# NUC100CN_v1 register map
File version: 1.0
Registers are 32-bit, read-write, reset 0x0 unless marked. A register's access mark holds for its fields unless they carry their own. Offsets are from the block's base; [hi:lo] are bit positions; {n}, {i} and the like mark numbered series; 'fields as' and 'values as' point back to an identical list.

## GP — GP Register Map
Base 0x50004000
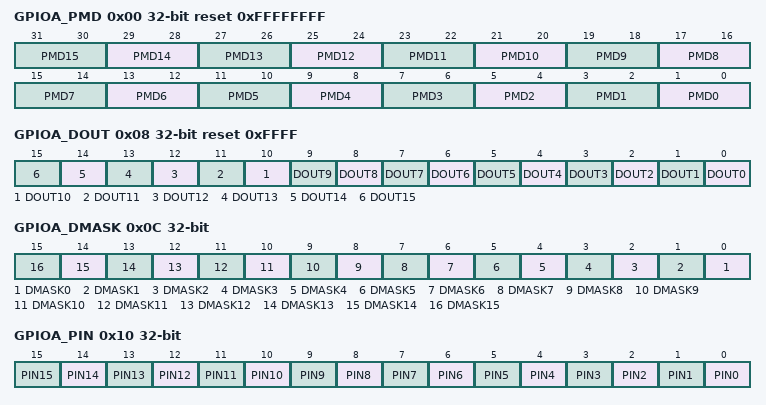
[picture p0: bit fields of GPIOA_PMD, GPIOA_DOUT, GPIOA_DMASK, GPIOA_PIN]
0x00 GPIOA_PMD reset 0xFFFFFFFF — GPIO Port A Pin I/O Mode Control
  [all] fields
    0=GPIO port [n] pin is in INPUT mode; 1=GPIO port [n] pin is in OUTPUT mode; 2=GPIO port [n] pin is in Open-Drain mode; 3=GPIO port [n] pin is in Quasi-bidirectional mode
  [2n+1:2n] PMD{n} (n=0..15) — GPIOx I/O Pin[n] Mode Control. Determine each I/O type of GPIOx pins.
0x04 GPIOA_OFFD — GPIO Port A Pin Digital Input Path Disable Control
  [31:16] OFFD — GPIOx Pin[n] Digital Input Path Disable Control. Each of these bits is used to control if the digital input path of corresponding GPIO pin is disabled. If input is analog signal, users can disable GPIO digital input path to avoid creepage
    0=I/O digital input path Enabled; 1=I/O digital input path Disabled (digital input tied to low)
0x08 GPIOA_DOUT reset 0xFFFF — GPIO Port A Data Output Value
  [all] fields
    0=GPIO port [A/B/C/D/E] Pin[n] will drive Low if the GPIO pin is configures as output, open-drain and quasi-mode; 1=GPIO port [A/B/C/D/E] Pin[n] will drive High if the GPIO pin is configures as output, open-drain and quasi-mode
  [n] DOUT{n} (n=0..15) — GPIOx Pin[n] Output Value. Each of these bits control the status of a GPIO pin when the GPIO pin is configures as output, open-drain and quasi-mode.
0x0C GPIOA_DMASK — GPIO Port A Data Output Write Mask
  [all] fields
    0=The corresponding GPIOx_DOUT[n] bit can be updated; 1=The corresponding GPIOx_DOUT[n] bit is protected
  [n] DMASK{n} (n=0..15) — Port [A/B/C/D/E] Data Output Write Mask. These bits are used to protect the corresponding register of GPIOx_DOUT bit[n]. When set the DMASK bit[n] to 1, the corresponding GPIOx_DOUT[n] bit is protected. The write signal is masked, write data to the protect bit is ignored. Note: This function only protect corresponding GPIOx_DOUT[n] bit, and will not protect corresponding bit control register (GPIOAx_DOUT, GPIOBx_DOUT, GPIOCx_DOUT, GPIODx_DOUT, GPIOEx_DOUT).
0x10 GPIOA_PIN ro (reset mask 0xFFFF0000) — GPIO Port A Pin Value
  [n] PIN{n} (n=0..15) — Port [A/B/C/D/E] Pin Values. Each bit of the register reflects the actual status of the respective GPIO pin If bit is 1, it indicates the corresponding pin status is high, else the pin status is low
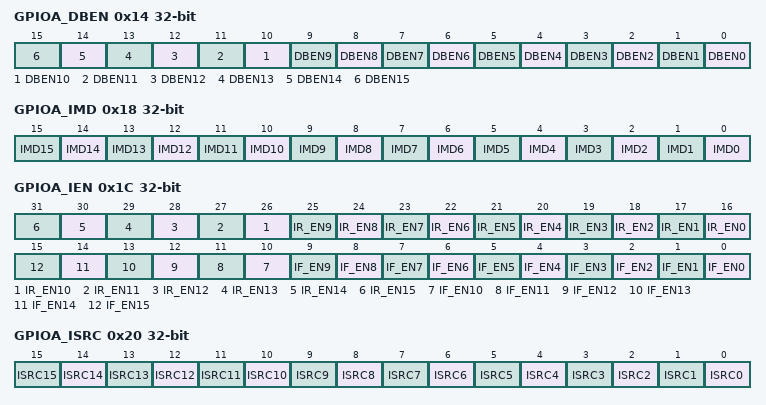
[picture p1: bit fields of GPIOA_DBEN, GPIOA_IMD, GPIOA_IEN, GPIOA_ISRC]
0x14 GPIOA_DBEN — GPIO Port A De-bounce Enable
  [all] fields
    0=The bit[n] de-bounce function Disabled; 1=The bit[n] de-bounce function Enabled
  [n] DBEN{n} (n=0..15) — Port [A/B/C/D/E] Input Signal De-bounce Enable. DBEN[n]used to enable the de-bounce function for each corresponding bit. If the input signal pulse width cannot be sampled by continuous two de-bounce sample cycle The input signal transition is seen as the signal bounce and will not trigger the interrupt. The de-bounce clock source is controlled by DBNCECON[4], one de-bounce sample cycle is controlled by DBNCECON[3:0]. The de-bounce function is valid for edge triggered interrupt. If the interrupt mode is level triggered, the de-bounce enable bit is ignored. Note: It is recommended setting this bit to '0' if GPIO is chosen as power down wakeup source. If set this bit to '1', will cause GPIO to produce interrupt twice. One is caused by wake up event, the other one is caused by delayed de-bounce result.
0x18 GPIOA_IMD — GPIO Port A Interrupt Mode Control
  [all] fields
    0=Edge trigger interrupt; 1=Level trigger interrupt
  [n] IMD{n} (n=0..15) — Port [A/B/C/D/E] Edge or Level Detection Interrupt Control. IMD[n] is used to control the interrupt is by level trigger or by edge trigger. If the interrupt is by edge trigger, the trigger source can be controlled by de-bounce. If the interrupt is by level trigger, the input source is sampled by one HCLK clock and generates the interrupt. If set pin as the level trigger interrupt, then only one level can be set on the registers GPIOx_IEN. If set both the level to trigger interrupt, the setting is ignored and no interrupt will occur. The de-bounce function is valid for edge triggered interrupt. If the interrupt mode is level triggered, the de-bounce enable bit is ignored.
0x1C GPIOA_IEN — GPIO Port A Interrupt Enable
  [n+16] IR_EN{n} (n=0..15) — Port [A/B/C/D/E] Interrupt Enable by Input Rising Edge or Input Level High. IR_EN[n] used to enable the interrupt for each of the corresponding input GPIO_PIN[n]. Set bit to 1 also enable the pin wake-up function. When set the IR_EN[n] bit to 1: If the interrupt is level trigger, the input PIN[n] state at level "high" will generate the interrupt. If the interrupt is edge trigger, the input PIN[n] state change from "low-to-high" will generate the interrupt.
    0=PIN[n] level-high or low-to-high interrupt Disabled; 1=PIN[n] level-high or low-to-high interrupt Enabled
  [n] IF_EN{n} (n=0..15) — Port [A/B/C/D/E] Interrupt Enable by Input Falling Edge or Input Level Low. IF_EN[n] used to enable the interrupt for each of the corresponding input GPIO_PIN[n]. Set bit to 1 also enable the pin wake-up function. When set the IF_EN[n] bit to 1: If the interrupt is level trigger, the input PIN[n] state at level "low" will generate the interrupt. If the interrupt is edge trigger, the input PIN[n] state change from "high-to-low" will generate the interrupt.
    0=PIN[n] state low-level or high-to-low change interrupt Disabled; 1=PIN[n] state low-level or high-to-low change interrupt Enabled
0x20 GPIOA_ISRC reset not defined — GPIO Port A Interrupt Source Flag
  [all] fields
    0=No interrupt at GPIOx[n]. No action; 1=Indicates GPIOx[n] generate an interrupt. Clear the correspond pending interrupt
  [n] ISRC{n} (n=0..15) — Port [A/B/C/D/E] Interrupt Source Flag. Read :
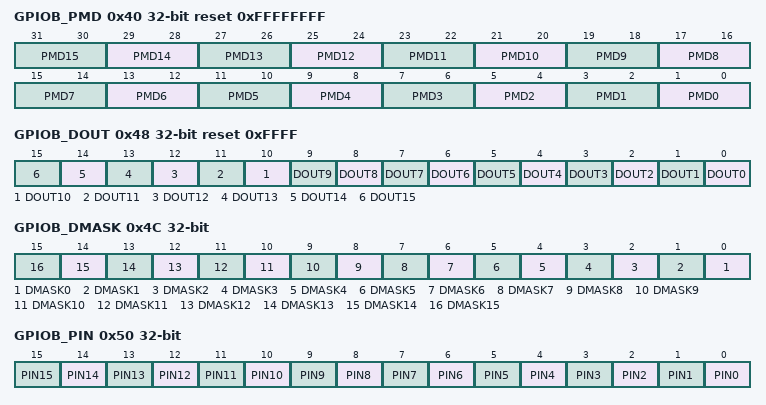
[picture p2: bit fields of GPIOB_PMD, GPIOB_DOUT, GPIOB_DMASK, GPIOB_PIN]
0x40 GPIOB_PMD reset 0xFFFFFFFF — GPIO Port B Pin I/O Mode Control
  fields as GPIOA_PMD
0x44 GPIOB_OFFD — GPIO Port B Pin Digital Input Path Disable Control
  fields as GPIOA_OFFD
0x48 GPIOB_DOUT reset 0xFFFF — GPIO Port B Data Output Value
  fields as GPIOA_DOUT
0x4C GPIOB_DMASK — GPIO Port B Data Output Write Mask
  fields as GPIOA_DMASK
0x50 GPIOB_PIN ro (reset mask 0xFFFF0000) — GPIO Port B Pin Value
  fields as GPIOA_PIN
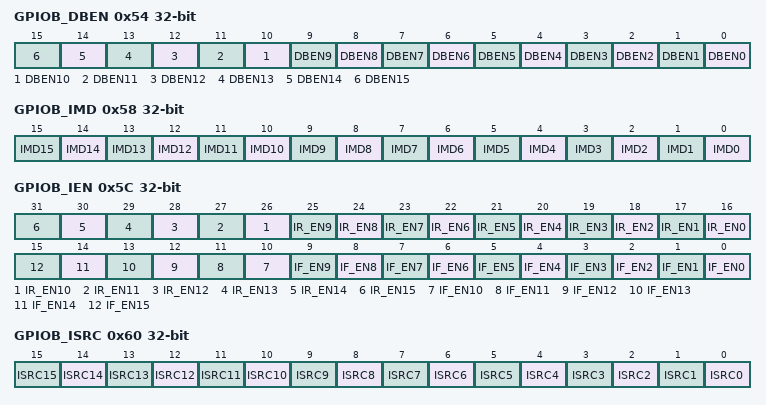
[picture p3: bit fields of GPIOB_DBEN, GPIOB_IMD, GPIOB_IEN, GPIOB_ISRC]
0x54 GPIOB_DBEN — GPIO Port B De-bounce Enable
  fields as GPIOA_DBEN
0x58 GPIOB_IMD — GPIO Port B Interrupt Mode Control
  fields as GPIOA_IMD
0x5C GPIOB_IEN — GPIO Port B Interrupt Enable
  fields as GPIOA_IEN
0x60 GPIOB_ISRC reset not defined — GPIO Port B Interrupt Source Flag
  fields as GPIOA_ISRC
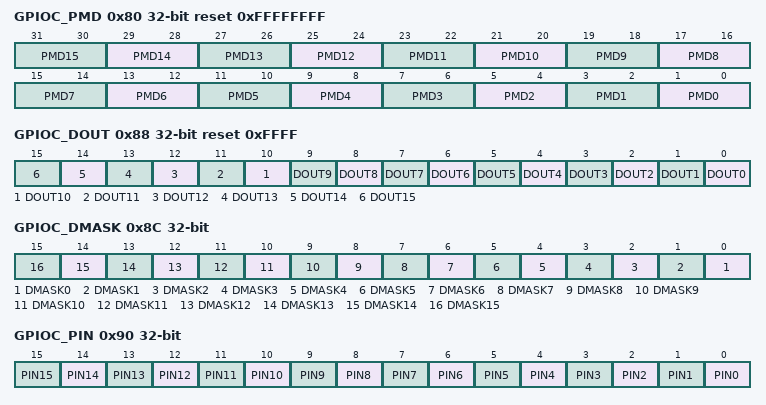
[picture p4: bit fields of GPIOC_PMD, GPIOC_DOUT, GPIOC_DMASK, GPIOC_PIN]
0x80 GPIOC_PMD reset 0xFFFFFFFF — GPIO Port C Pin I/O Mode Control
  fields as GPIOA_PMD
0x84 GPIOC_OFFD — GPIO Port C Pin Digital Input Path Disable Control
  fields as GPIOA_OFFD
0x88 GPIOC_DOUT reset 0xFFFF — GPIO Port C Data Output Value
  fields as GPIOA_DOUT
0x8C GPIOC_DMASK — GPIO Port C Data Output Write Mask
  fields as GPIOA_DMASK
0x90 GPIOC_PIN ro (reset mask 0xFFFF0000) — GPIO Port C Pin Value
  fields as GPIOA_PIN
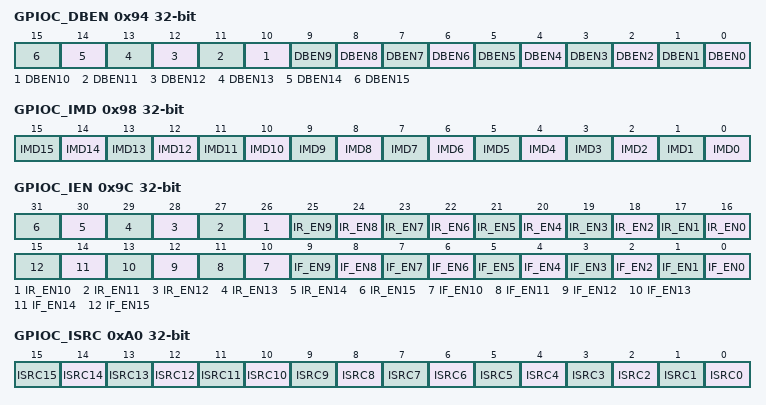
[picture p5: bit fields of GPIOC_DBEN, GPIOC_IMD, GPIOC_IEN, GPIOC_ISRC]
0x94 GPIOC_DBEN — GPIO Port C De-bounce Enable
  fields as GPIOA_DBEN
0x98 GPIOC_IMD — GPIO Port C Interrupt Mode Control
  fields as GPIOA_IMD
0x9C GPIOC_IEN — GPIO Port C Interrupt Enable
  fields as GPIOA_IEN
0xA0 GPIOC_ISRC reset not defined — GPIO Port C Interrupt Source Flag
  fields as GPIOA_ISRC
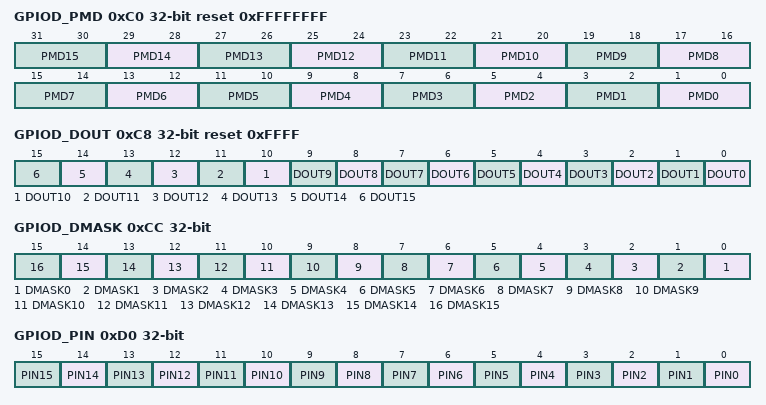
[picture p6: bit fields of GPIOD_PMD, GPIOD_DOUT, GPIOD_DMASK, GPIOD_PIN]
0xC0 GPIOD_PMD reset 0xFFFFFFFF — GPIO Port D Pin I/O Mode Control
  fields as GPIOA_PMD
0xC4 GPIOD_OFFD — GPIO Port D Pin Digital Input Path Disable Control
  fields as GPIOA_OFFD
0xC8 GPIOD_DOUT reset 0xFFFF — GPIO Port D Data Output Value
  fields as GPIOA_DOUT
0xCC GPIOD_DMASK — GPIO Port D Data Output Write Mask
  fields as GPIOA_DMASK
0xD0 GPIOD_PIN ro (reset mask 0xFFFF0000) — GPIO Port D Pin Value
  fields as GPIOA_PIN
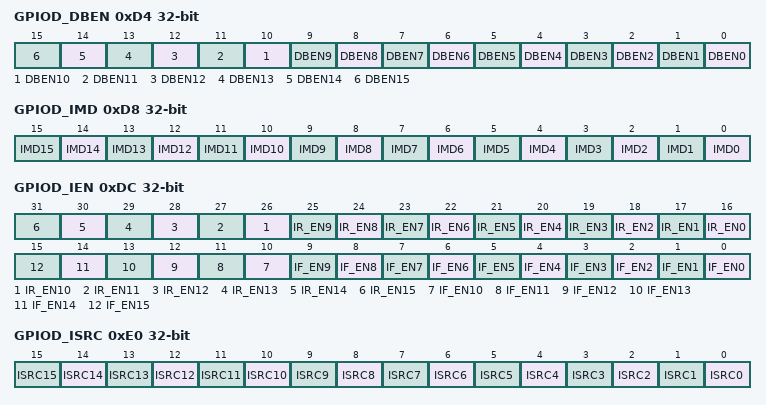
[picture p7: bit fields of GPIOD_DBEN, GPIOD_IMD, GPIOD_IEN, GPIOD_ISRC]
0xD4 GPIOD_DBEN — GPIO Port D De-bounce Enable
  fields as GPIOA_DBEN
0xD8 GPIOD_IMD — GPIO Port D Interrupt Mode Control
  fields as GPIOA_IMD
0xDC GPIOD_IEN — GPIO Port D Interrupt Enable
  fields as GPIOA_IEN
0xE0 GPIOD_ISRC reset not defined — GPIO Port D Interrupt Source Flag
  fields as GPIOA_ISRC
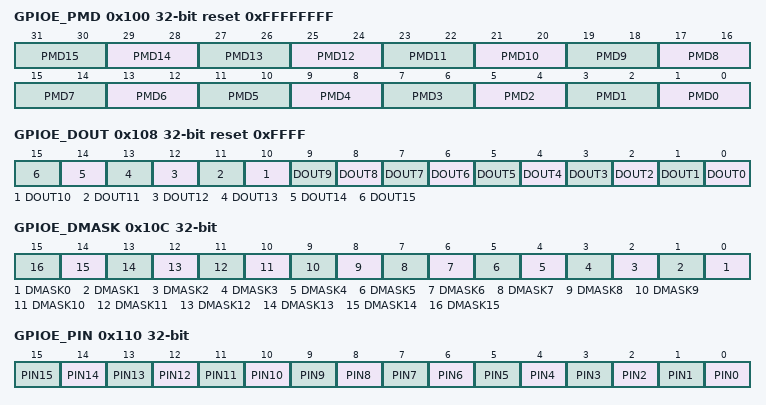
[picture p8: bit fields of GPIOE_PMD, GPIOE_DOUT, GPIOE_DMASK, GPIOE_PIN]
0x100 GPIOE_PMD reset 0xFFFFFFFF — GPIO Port E Pin I/O Mode Control
  fields as GPIOA_PMD
0x104 GPIOE_OFFD — GPIO Port E Pin Digital Input Path Disable Control
  fields as GPIOA_OFFD
0x108 GPIOE_DOUT reset 0xFFFF — GPIO Port E Data Output Value
  fields as GPIOA_DOUT
0x10C GPIOE_DMASK — GPIO Port E Data Output Write Mask
  fields as GPIOA_DMASK
0x110 GPIOE_PIN ro (reset mask 0xFFFF0000) — GPIO Port E Pin Value
  fields as GPIOA_PIN
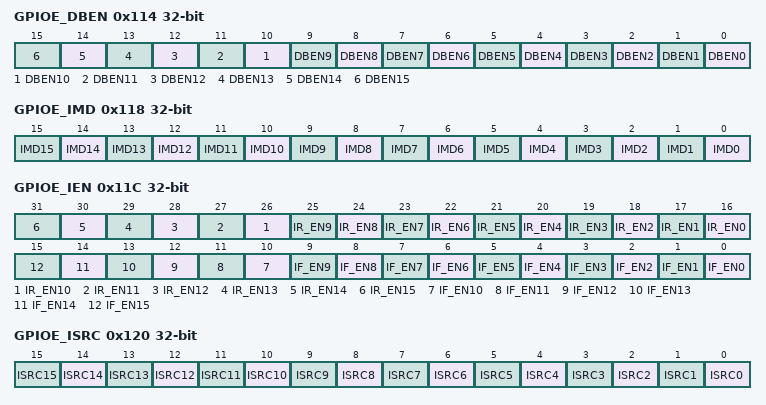
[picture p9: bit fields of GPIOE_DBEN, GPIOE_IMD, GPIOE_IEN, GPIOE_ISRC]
0x114 GPIOE_DBEN — GPIO Port E De-bounce Enable
  fields as GPIOA_DBEN
0x118 GPIOE_IMD — GPIO Port E Interrupt Mode Control
  fields as GPIOA_IMD
0x11C GPIOE_IEN — GPIO Port E Interrupt Enable
  fields as GPIOA_IEN
0x120 GPIOE_ISRC reset not defined — GPIO Port E Interrupt Source Flag
  fields as GPIOA_ISRC
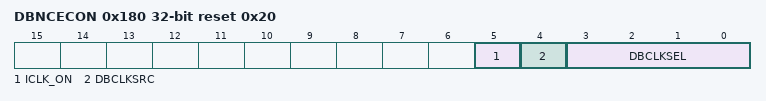
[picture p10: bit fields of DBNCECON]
0x180 DBNCECON reset 0x20 — De-bounce Cycle Control
  [5] ICLK_ON — Interrupt clock On mode. It is recommended to turn off this bit to save system power, if on special application concern.
    0=Edge detection circuit is active only if the I/O pin corresponding to GPIOx_IEN bit is set to 1; 1=All I/O pins edge detection circuit is always active after reset
  [4] DBCLKSRC — De-bounce counter clock source select
    0=De-bounce counter clock source is the HCLK; 1=De-bounce counter clock source is the internal 10 kHz low speed oscillator
  [3:0] DBCLKSEL — De-bounce sampling cycle selection
0x200 PA0_PDIO reset 0x1 — GPIO PA.0 Pin Data I/O
  [0] Pxn_PDIO — GPIO Px.n Pin Data I/O. Write this bit can control one GPIO pin output value. Read this register to get GPIO pin status. For example: write PA0_PDIO will reflect the written value to bit GPIOA_DOUT[0], read PA0_PDIO will return the value of GPIOA_PIN[0]. Note: The write operation will not be affected by register GPIOx_DMASK
    0=Set corresponding GPIO pin to low; 1=Set corresponding GPIO pin to high
0x204 PA1_PDIO reset 0x1 — GPIO PA.1 Pin Data I/O
  fields as PA0_PDIO
0x208 PA2_PDIO reset 0x1 — GPIO PA.2 Pin Data I/O
  fields as PA0_PDIO
0x20C PA3_PDIO reset 0x1 — GPIO PA.3 Pin Data I/O
  fields as PA0_PDIO
0x210 PA4_PDIO reset 0x1 — GPIO PA.4 Pin Data I/O
  fields as PA0_PDIO
0x214 PA5_PDIO reset 0x1 — GPIO PA.5 Pin Data I/O
  fields as PA0_PDIO
0x218 PA6_PDIO reset 0x1 — GPIO PA.6 Pin Data I/O
  fields as PA0_PDIO
0x21C PA7_PDIO reset 0x1 — GPIO PA.7 Pin Data I/O
  fields as PA0_PDIO
0x220 PA8_PDIO reset 0x1 — GPIO PA.8 Pin Data I/O
  fields as PA0_PDIO
0x224 PA9_PDIO reset 0x1 — GPIO PA.9 Pin Data I/O
  fields as PA0_PDIO
0x228 PA10_PDIO reset 0x1 — GPIO PA.10 Pin Data I/O
  fields as PA0_PDIO
0x22C PA11_PDIO reset 0x1 — GPIO PA.11 Pin Data I/O
  fields as PA0_PDIO
0x230 PA12_PDIO reset 0x1 — GPIO PA.12 Pin Data I/O
  fields as PA0_PDIO
0x234 PA13_PDIO reset 0x1 — GPIO PA.13 Pin Data I/O
  fields as PA0_PDIO
0x238 PA14_PDIO reset 0x1 — GPIO PA.14 Pin Data I/O
  fields as PA0_PDIO
0x23C PA15_PDIO reset 0x1 — GPIO PA.15 Pin Data I/O
  fields as PA0_PDIO
0x240 PB0_PDIO reset 0x1 — GPIO PB.0 Pin Data I/O
  fields as PA0_PDIO
0x244 PB1_PDIO reset 0x1 — GPIO PB.1 Pin Data I/O
  fields as PA0_PDIO
0x248 PB2_PDIO reset 0x1 — GPIO PB.2 Pin Data I/O
  fields as PA0_PDIO
0x24C PB3_PDIO reset 0x1 — GPIO PB.3 Pin Data I/O
  fields as PA0_PDIO
0x250 PB4_PDIO reset 0x1 — GPIO PB.4 Pin Data I/O
  fields as PA0_PDIO
0x254 PB5_PDIO reset 0x1 — GPIO PB.5 Pin Data I/O
  fields as PA0_PDIO
0x258 PB6_PDIO reset 0x1 — GPIO PB.6 Pin Data I/O
  fields as PA0_PDIO
0x25C PB7_PDIO reset 0x1 — GPIO PB.7 Pin Data I/O
  fields as PA0_PDIO
0x260 PB8_PDIO reset 0x1 — GPIO PB.8 Pin Data I/O
  fields as PA0_PDIO
0x264 PB9_PDIO reset 0x1 — GPIO PB.9 Pin Data I/O
  fields as PA0_PDIO
0x268 PB10_PDIO reset 0x1 — GPIO PB.10 Pin Data I/O
  fields as PA0_PDIO
0x26C PB11_PDIO reset 0x1 — GPIO PB.11 Pin Data I/O
  fields as PA0_PDIO
0x270 PB12_PDIO reset 0x1 — GPIO PB.12 Pin Data I/O
  fields as PA0_PDIO
0x274 PB13_PDIO reset 0x1 — GPIO PB.13 Pin Data I/O
  fields as PA0_PDIO
0x278 PB14_PDIO reset 0x1 — GPIO PB.14 Pin Data I/O
  fields as PA0_PDIO
0x27C PB15_PDIO reset 0x1 — GPIO PB.15 Pin Data I/O
  fields as PA0_PDIO
0x280 PC0_PDIO reset 0x1 — GPIO PC.0 Pin Data I/O
  fields as PA0_PDIO
0x284 PC1_PDIO reset 0x1 — GPIO PC.1 Pin Data I/O
  fields as PA0_PDIO
0x288 PC2_PDIO reset 0x1 — GPIO PC.2 Pin Data I/O
  fields as PA0_PDIO
0x28C PC3_PDIO reset 0x1 — GPIO PC.3 Pin Data I/O
  fields as PA0_PDIO
0x290 PC4_PDIO reset 0x1 — GPIO PC.4 Pin Data I/O
  fields as PA0_PDIO
0x294 PC5_PDIO reset 0x1 — GPIO PC.5 Pin Data I/O
  fields as PA0_PDIO
0x298 PC6_PDIO reset 0x1 — GPIO PC.6 Pin Data I/O
  fields as PA0_PDIO
0x29C PC7_PDIO reset 0x1 — GPIO PC.7 Pin Data I/O
  fields as PA0_PDIO
0x2A0 PC8_PDIO reset 0x1 — GPIO PC.8 Pin Data I/O
  fields as PA0_PDIO
0x2A4 PC9_PDIO reset 0x1 — GPIO PC.9 Pin Data I/O
  fields as PA0_PDIO
0x2A8 PC10_PDIO reset 0x1 — GPIO PC.10 Pin Data I/O
  fields as PA0_PDIO
0x2AC PC11_PDIO reset 0x1 — GPIO PC.11 Pin Data I/O
  fields as PA0_PDIO
0x2B0 PC12_PDIO reset 0x1 — GPIO PC.12 Pin Data I/O
  fields as PA0_PDIO
0x2B4 PC13_PDIO reset 0x1 — GPIO PC.13 Pin Data I/O
  fields as PA0_PDIO
0x2B8 PC14_PDIO reset 0x1 — GPIO PC.14 Pin Data I/O
  fields as PA0_PDIO
0x2BC PC15_PDIO reset 0x1 — GPIO PC.15 Pin Data I/O
  fields as PA0_PDIO
0x2C0 PD0_PDIO reset 0x1 — GPIO PD.0 Pin Data I/O
  fields as PA0_PDIO
0x2C4 PD1_PDIO reset 0x1 — GPIO PD.1 Pin Data I/O
  fields as PA0_PDIO
0x2C8 PD2_PDIO reset 0x1 — GPIO PD.2 Pin Data I/O
  fields as PA0_PDIO
0x2CC PD3_PDIO reset 0x1 — GPIO PD.3 Pin Data I/O
  fields as PA0_PDIO
0x2D0 PD4_PDIO reset 0x1 — GPIO PD.4 Pin Data I/O
  fields as PA0_PDIO
0x2D4 PD5_PDIO reset 0x1 — GPIO PD.5 Pin Data I/O
  fields as PA0_PDIO
0x2D8 PD6_PDIO reset 0x1 — GPIO PD.6 Pin Data I/O
  fields as PA0_PDIO
0x2DC PD7_PDIO reset 0x1 — GPIO PD.7 Pin Data I/O
  fields as PA0_PDIO
0x2E0 PD8_PDIO reset 0x1 — GPIO PD.8 Pin Data I/O
  fields as PA0_PDIO
0x2E4 PD9_PDIO reset 0x1 — GPIO PD.9 Pin Data I/O
  fields as PA0_PDIO
0x2E8 PD10_PDIO reset 0x1 — GPIO PD.10 Pin Data I/O
  fields as PA0_PDIO
0x2EC PD11_PDIO reset 0x1 — GPIO PD.11 Pin Data I/O
  fields as PA0_PDIO
0x2F0 PD12_PDIO reset 0x1 — GPIO PD.12 Pin Data I/O
  fields as PA0_PDIO
0x2F4 PD13_PDIO reset 0x1 — GPIO PD.13 Pin Data I/O
  fields as PA0_PDIO
0x2F8 PD14_PDIO reset 0x1 — GPIO PD.14 Pin Data I/O
  fields as PA0_PDIO
0x2FC PD15_PDIO reset 0x1 — GPIO PD.15 Pin Data I/O
  fields as PA0_PDIO
0x300 PE0_PDIO reset 0x1 — GPIO PE.0 Pin Data I/O
  fields as PA0_PDIO
0x304 PE1_PDIO reset 0x1 — GPIO PE.1 Pin Data I/O
  fields as PA0_PDIO
0x308 PE2_PDIO reset 0x1 — GPIO PE.2 Pin Data I/O
  fields as PA0_PDIO
0x30C PE3_PDIO reset 0x1 — GPIO PE.3 Pin Data I/O
  fields as PA0_PDIO
0x310 PE4_PDIO reset 0x1 — GPIO PE.4 Pin Data I/O
  fields as PA0_PDIO
0x314 PE5_PDIO reset 0x1 — GPIO PE.5 Pin Data I/O
  fields as PA0_PDIO
0x318 PE6_PDIO reset 0x1 — GPIO PE.6 Pin Data I/O
  fields as PA0_PDIO
0x31C PE7_PDIO reset 0x1 — GPIO PE.7 Pin Data I/O
  fields as PA0_PDIO
0x320 PE8_PDIO reset 0x1 — GPIO PE.8 Pin Data I/O
  fields as PA0_PDIO
0x324 PE9_PDIO reset 0x1 — GPIO PE.9 Pin Data I/O
  fields as PA0_PDIO
0x328 PE10_PDIO reset 0x1 — GPIO PE.10 Pin Data I/O
  fields as PA0_PDIO
0x32C PE11_PDIO reset 0x1 — GPIO PE.11 Pin Data I/O
  fields as PA0_PDIO
0x330 PE12_PDIO reset 0x1 — GPIO PE.12 Pin Data I/O
  fields as PA0_PDIO
0x334 PE13_PDIO reset 0x1 — GPIO PE.13 Pin Data I/O
  fields as PA0_PDIO
0x338 PE14_PDIO reset 0x1 — GPIO PE.14 Pin Data I/O
  fields as PA0_PDIO
0x33C PE15_PDIO reset 0x1 — GPIO PE.15 Pin Data I/O
  fields as PA0_PDIO
